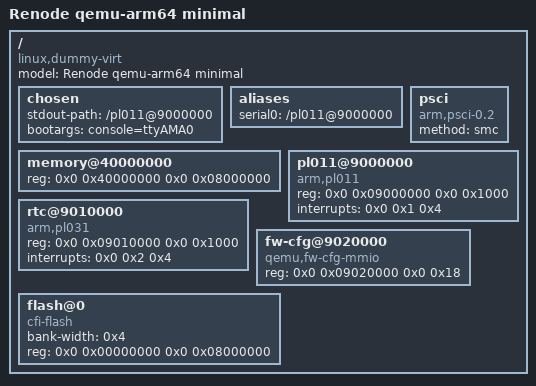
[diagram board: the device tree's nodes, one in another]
/dts-v1/;

/ {
    #address-cells = <0x2>;
    #size-cells = <0x2>;
    compatible = "linux,dummy-virt";
    model = "Renode qemu-arm64 minimal";

    chosen {
        stdout-path = "/pl011@9000000";
        bootargs = "console=ttyAMA0";
    };

    aliases {
        serial0 = "/pl011@9000000";
    };

    psci {
        compatible = "arm,psci-0.2";
        method = "smc";
    };

    memory@40000000 {
        device_type = "memory";
        reg = <0x0 0x40000000 0x0 0x08000000>;
    };

    pl011@9000000 {
        compatible = "arm,pl011", "arm,primecell";
        reg = <0x0 0x09000000 0x0 0x1000>;
        interrupts = <0x0 0x1 0x4>;
    };

    rtc@9010000 {
        compatible = "arm,pl031", "arm,primecell";
        reg = <0x0 0x09010000 0x0 0x1000>;
        interrupts = <0x0 0x2 0x4>;
    };

    fw-cfg@9020000 {
        compatible = "qemu,fw-cfg-mmio";
        reg = <0x0 0x09020000 0x0 0x18>;
    };

    flash@0 {
        compatible = "cfi-flash";
        bank-width = <0x4>;
        reg = <0x0 0x00000000 0x0 0x08000000>;
    };
};
